VERSION ""

NS_ :

BS_:

BU_: BMS ECU

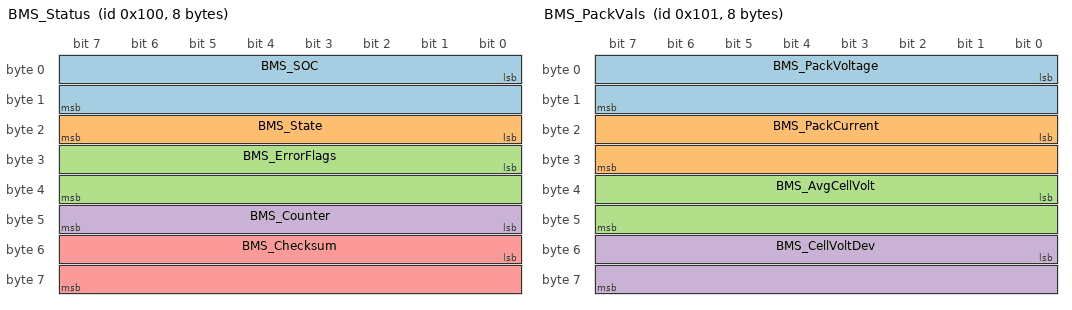
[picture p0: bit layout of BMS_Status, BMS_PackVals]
BO_ 256 BMS_Status: 8 BMS
 SG_ BMS_SOC : 0|16@1+ (0.1,0) [0|100] "%" Vector__XXX
 SG_ BMS_State : 16|8@1+ (1,0) [0|10] "" Vector__XXX
 SG_ BMS_ErrorFlags : 24|16@1+ (1,0) [0|65535] "" Vector__XXX
 SG_ BMS_Counter : 40|8@1+ (1,0) [0|255] "" Vector__XXX
 SG_ BMS_Checksum : 48|16@1+ (1,0) [0|65535] "" Vector__XXX

BO_ 257 BMS_PackVals: 8 BMS
 SG_ BMS_PackVoltage : 0|16@1+ (0.1,0) [0|1000] "V" Vector__XXX
 SG_ BMS_PackCurrent : 16|16@1+ (0.1,-1000) [-1000|1000] "A" Vector__XXX
 SG_ BMS_AvgCellVolt : 32|16@1+ (0.001,0) [0|5] "V" Vector__XXX
 SG_ BMS_CellVoltDev : 48|16@1+ (0.001,0) [0|1] "V" Vector__XXX

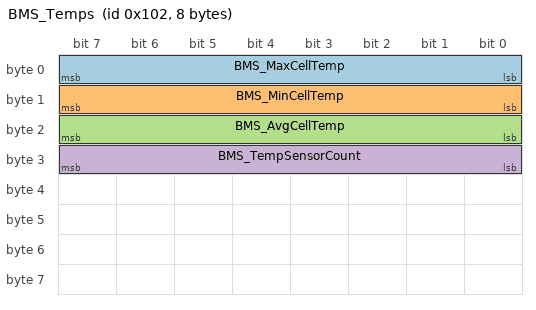
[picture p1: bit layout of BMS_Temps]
BO_ 258 BMS_Temps: 8 BMS
 SG_ BMS_MaxCellTemp : 0|8@1+ (1,-40) [-40|125] "C" Vector__XXX
 SG_ BMS_MinCellTemp : 8|8@1+ (1,-40) [-40|125] "C" Vector__XXX
 SG_ BMS_AvgCellTemp : 16|8@1+ (1,-40) [-40|125] "C" Vector__XXX
 SG_ BMS_TempSensorCount : 24|8@1+ (1,0) [0|64] "" Vector__XXX

CM_ BO_ 256 "BMS Status, containing State of Charge, internal operational states, and system error indicators.";
CM_ SG_ 256 BMS_ErrorFlags "Bitmask of BMS faults: Bit0=OverVoltage, Bit1=UnderVoltage, Bit2=OverTemp, Bit3=UnderTemp, Bit4=CommFault";
CM_ BO_ 257 "BMS Pack values, including high voltage metrics and current dynamics.";
CM_ BO_ 258 "BMS Temperature measurements representing physical cell conditions.";

VAL_ 256 BMS_State 0 "Init" 1 "Ready" 2 "Charging" 3 "Discharging" 4 "Fault" 5 "Shutdown";
